# STM32F427x register map
File version: 1.0
Registers are 32-bit, read-write, reset 0x0 unless marked. A register's access mark holds for its fields unless they carry their own. Offsets are from the block's base; [hi:lo] are bit positions; {n}, {i} and the like mark numbered series.

## RNG — Random number generator
Base 0x50060800
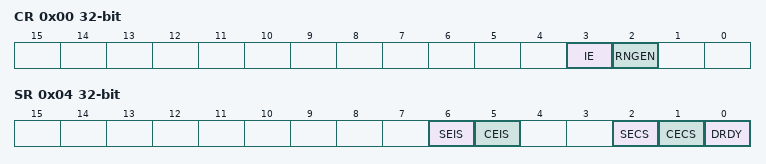
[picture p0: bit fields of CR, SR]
0x00 CR — control register
  [3] IE — Interrupt enable
  [2] RNGEN — Random number generator enable
0x04 SR access per field — status register
  [6] SEIS rw — Seed error interrupt status
  [5] CEIS rw — Clock error interrupt status
  [2] SECS ro — Seed error current status
  [1] CECS ro — Clock error current status
  [0] DRDY ro — Data ready
0x08 DR ro — data register
  [31:0] RNDATA — Random data

## DCMI — Digital camera interface
Base 0x50050000
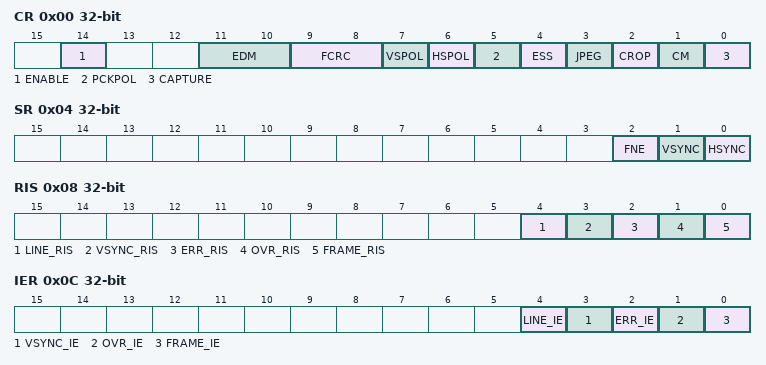
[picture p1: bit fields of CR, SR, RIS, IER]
0x00 CR — control register 1
  [14] ENABLE — DCMI enable
  [11:10] EDM — Extended data mode
  [9:8] FCRC — Frame capture rate control
  [7] VSPOL — Vertical synchronization polarity
  [6] HSPOL — Horizontal synchronization polarity
  [5] PCKPOL — Pixel clock polarity
  [4] ESS — Embedded synchronization select
  [3] JPEG — JPEG format
  [2] CROP — Crop feature
  [1] CM — Capture mode
  [0] CAPTURE — Capture enable
0x04 SR ro — status register
  [2] FNE — FIFO not empty
  [1] VSYNC
  [0] HSYNC
0x08 RIS ro — raw interrupt status register
  [4] LINE_RIS — Line raw interrupt status
  [3] VSYNC_RIS — VSYNC raw interrupt status
  [2] ERR_RIS — Synchronization error raw interrupt status
  [1] OVR_RIS — Overrun raw interrupt status
  [0] FRAME_RIS — Capture complete raw interrupt status
0x0C IER — interrupt enable register
  [4] LINE_IE — Line interrupt enable
  [3] VSYNC_IE — VSYNC interrupt enable
  [2] ERR_IE — Synchronization error interrupt enable
  [1] OVR_IE — Overrun interrupt enable
  [0] FRAME_IE — Capture complete interrupt enable
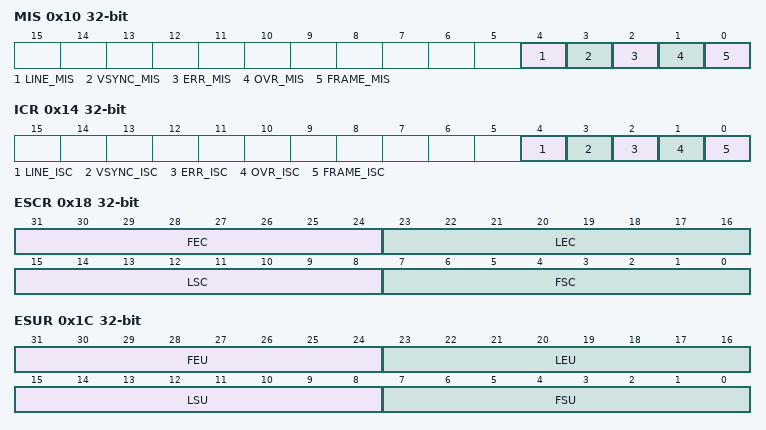
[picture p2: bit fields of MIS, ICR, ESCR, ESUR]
0x10 MIS ro — masked interrupt status register
  [4] LINE_MIS — Line masked interrupt status
  [3] VSYNC_MIS — VSYNC masked interrupt status
  [2] ERR_MIS — Synchronization error masked interrupt status
  [1] OVR_MIS — Overrun masked interrupt status
  [0] FRAME_MIS — Capture complete masked interrupt status
0x14 ICR wo — interrupt clear register
  [4] LINE_ISC — line interrupt status clear
  [3] VSYNC_ISC — Vertical synch interrupt status clear
  [2] ERR_ISC — Synchronization error interrupt status clear
  [1] OVR_ISC — Overrun interrupt status clear
  [0] FRAME_ISC — Capture complete interrupt status clear
0x18 ESCR — embedded synchronization code register
  [31:24] FEC — Frame end delimiter code
  [23:16] LEC — Line end delimiter code
  [15:8] LSC — Line start delimiter code
  [7:0] FSC — Frame start delimiter code
0x1C ESUR — embedded synchronization unmask register
  [31:24] FEU — Frame end delimiter unmask
  [23:16] LEU — Line end delimiter unmask
  [15:8] LSU — Line start delimiter unmask
  [7:0] FSU — Frame start delimiter unmask
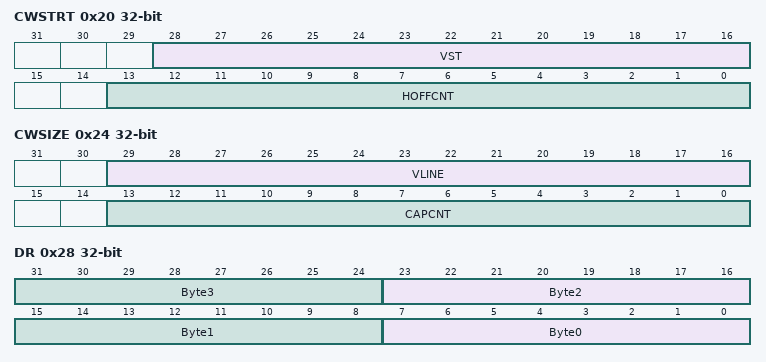
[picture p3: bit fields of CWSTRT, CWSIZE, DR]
0x20 CWSTRT — crop window start
  [28:16] VST — Vertical start line count
  [13:0] HOFFCNT — Horizontal offset count
0x24 CWSIZE — crop window size
  [29:16] VLINE — Vertical line count
  [13:0] CAPCNT — Capture count
0x28 DR ro — data register
  [8n+7:8n] Byte{n} (n=0..3) — Data byte {n}

## GPIOI — General-purpose I/Os
Base 0x40022000
Same registers: GPIOC 0x40020800, GPIOD 0x40020C00, GPIOE 0x40021000, GPIOF 0x40021400, GPIOG 0x40021800, GPIOH 0x40021C00
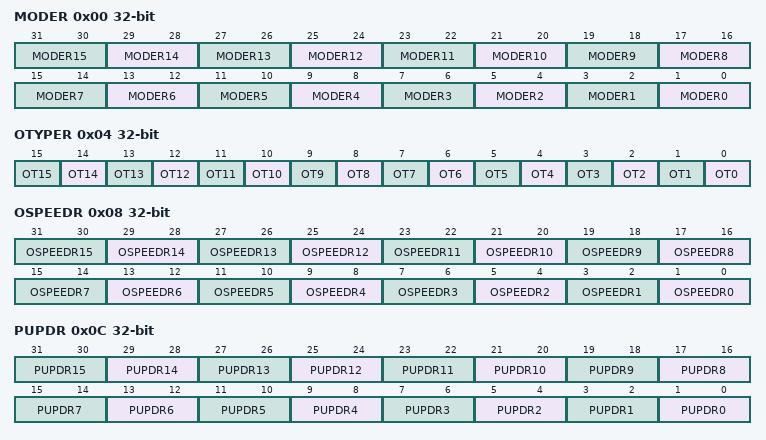
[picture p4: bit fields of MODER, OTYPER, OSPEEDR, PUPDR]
0x00 MODER — GPIO port mode register
  [2n+1:2n] MODER{n} (n=0..15) — Port x configuration bits (y = 0..15)
0x04 OTYPER — GPIO port output type register
  [n] OT{n} (n=0..15) — Port x configuration bits (y = 0..15)
0x08 OSPEEDR — GPIO port output speed register
  [2n+1:2n] OSPEEDR{n} (n=0..15) — Port x configuration bits (y = 0..15)
0x0C PUPDR — GPIO port pull-up/pull-down register
  [2n+1:2n] PUPDR{n} (n=0..15) — Port x configuration bits (y = 0..15)
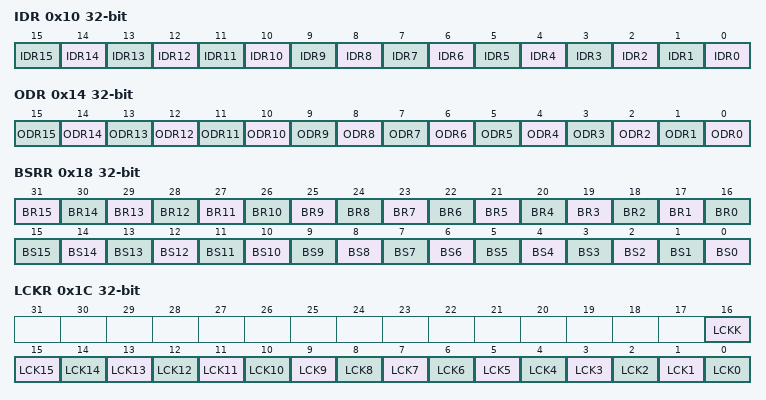
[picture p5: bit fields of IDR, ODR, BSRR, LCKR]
0x10 IDR ro — GPIO port input data register
  [n] IDR{n} (n=0..15) — Port input data (y = 0..15)
0x14 ODR — GPIO port output data register
  [n] ODR{n} (n=0..15) — Port output data (y = 0..15)
0x18 BSRR wo — GPIO port bit set/reset register
  [n+16] BR{n} (n=1..15) — Port x reset bit y (y = 0..15)
  [16] BR0 — Port x set bit y (y= 0..15)
  [n] BS{n} (n=0..15) — Port x set bit y (y= 0..15)
0x1C LCKR — GPIO port configuration lock register
  [16] LCKK — Port x lock bit y (y= 0..15)
  [n] LCK{n} (n=0..15) — Port x lock bit y (y= 0..15)
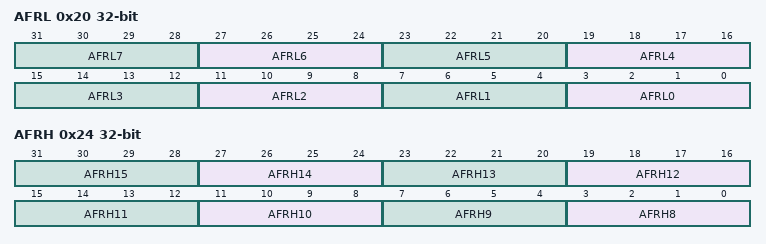
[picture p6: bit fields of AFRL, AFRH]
0x20 AFRL — GPIO alternate function low register
  [4n+3:4n] AFRL{n} (n=0..7) — Alternate function selection for port x bit y (y = 0..7)
0x24 AFRH — GPIO alternate function high register
  [4n-29:4n-32] AFRH{n} (n=8..15) — Alternate function selection for port x bit y (y = 8..15)

## GPIOB — General-purpose I/Os
Base 0x40020400
Registers as GPIOI; these are added or differ:
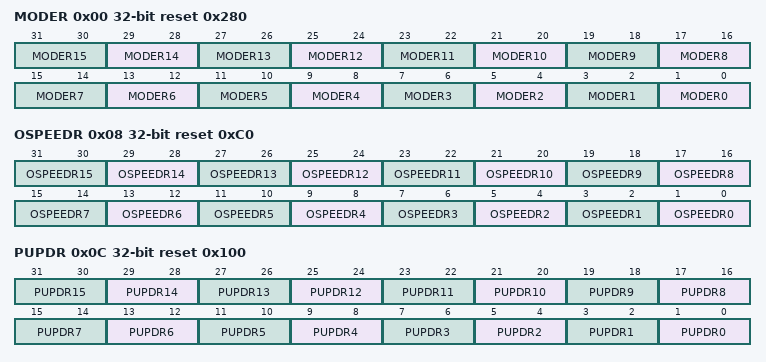
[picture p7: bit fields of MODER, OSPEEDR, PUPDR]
0x00 MODER reset 0x280 — GPIO port mode register
  [2n+1:2n] MODER{n} (n=0..15) — Port x configuration bits (y = 0..15)
0x08 OSPEEDR reset 0xC0 — GPIO port output speed register
  [2n+1:2n] OSPEEDR{n} (n=0..15) — Port x configuration bits (y = 0..15)
0x0C PUPDR reset 0x100 — GPIO port pull-up/pull-down register
  [2n+1:2n] PUPDR{n} (n=0..15) — Port x configuration bits (y = 0..15)

## GPIOA — General-purpose I/Os
Base 0x40020000
Registers as GPIOI; these are added or differ:
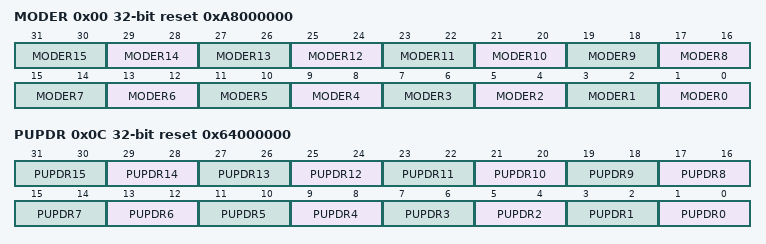
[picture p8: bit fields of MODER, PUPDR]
0x00 MODER reset 0xA8000000 — GPIO port mode register
  [2n+1:2n] MODER{n} (n=0..15) — Port x configuration bits (y = 0..15)
0x0C PUPDR reset 0x64000000 — GPIO port pull-up/pull-down register
  [2n+1:2n] PUPDR{n} (n=0..15) — Port x configuration bits (y = 0..15)
